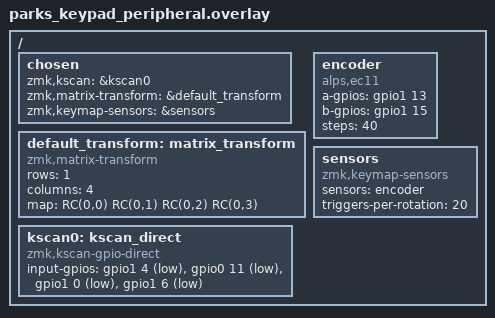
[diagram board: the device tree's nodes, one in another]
#include <dt-bindings/zmk/matrix_transform.h>

/ {
    chosen {
        zmk,kscan = &kscan0;
        zmk,matrix-transform = &default_transform;
        zmk,keymap-sensors = &sensors;
    };

    default_transform: matrix_transform {
        compatible = "zmk,matrix-transform";
        rows = <1>;
        columns = <4>;
        map = <
            RC(0,0) RC(0,1) RC(0,2) RC(0,3)
        >;
    };

    kscan0: kscan_direct {
        compatible = "zmk,kscan-gpio-direct";
        input-gpios
            = <&gpio1 4  (GPIO_ACTIVE_LOW | GPIO_PULL_UP)> // 1번: 1.04
            , <&gpio0 11 (GPIO_ACTIVE_LOW | GPIO_PULL_UP)> // 2번: 0.11
            , <&gpio1 0  (GPIO_ACTIVE_LOW | GPIO_PULL_UP)> // 3번: 1.00
            , <&gpio1 6  (GPIO_ACTIVE_LOW | GPIO_PULL_UP)> // 노브 클릭: 1.06
            ;
    };

    encoder: encoder {
        compatible = "alps,ec11";
        a-gpios = <&gpio1 13 (GPIO_ACTIVE_HIGH | GPIO_PULL_UP)>; // 우회전: 1.13
        b-gpios = <&gpio1 15 (GPIO_ACTIVE_HIGH | GPIO_PULL_UP)>; // 좌회전: 1.15
        steps = <40>; // 1틱당 확실한 트리거 보장
        status = "okay";
    };

    sensors: sensors {
        compatible = "zmk,keymap-sensors";
        sensors = <&encoder>;
        triggers-per-rotation = <20>;
    };
};
